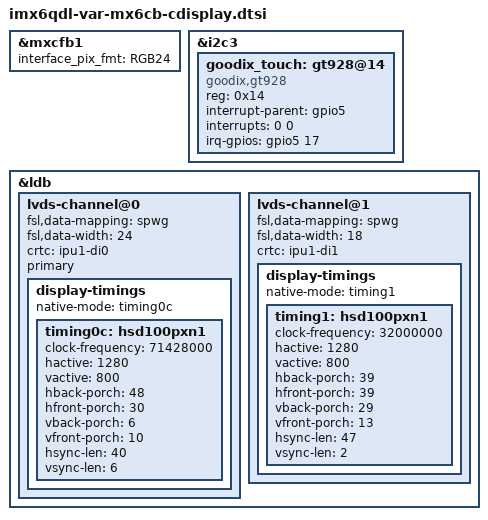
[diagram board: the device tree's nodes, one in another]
/*
 * Copyright (C) 2016 Variscite, Ltd. All Rights Reserved
 *
 * Copyright 2012 Freescale Semiconductor, Inc.
 * Copyright 2011 Linaro Ltd.
 *
 * The code contained herein is licensed under the GNU General Public
 * License. You may obtain a copy of the GNU General Public License
 * Version 2 or later at the following locations:
 *
 * http://www.opensource.org/licenses/gpl-license.html
 * http://www.gnu.org/copyleft/gpl.html
 *
 * Capacitive Display for VAR-MX6CustomBoard
 */

&mxcfb1 {
	interface_pix_fmt = "RGB24";
};

&i2c3 {
        goodix_touch: gt928@14 {
                compatible = "goodix,gt928";
                reg = <0x14>;
                interrupt-parent = <&gpio5>;
                interrupts = <0 0>;
                irq-gpios = <&gpio5 17>;
        };
};

&ldb {
	status = "okay";

	lvds-channel@0 {
		fsl,data-mapping = "spwg";
		fsl,data-width = <24>;
		status = "okay";
                crtc = "ipu1-di0";       /* ?? */
		primary;

		display-timings {
			native-mode = <&timing0c>;
			timing0c: hsd100pxn1 {
				clock-frequency = <71428000>;
				hactive = <1280>;
				vactive = <800>;
				hback-porch = <48>;
				hfront-porch = <30>;
				vback-porch = <6>;
				vfront-porch = <10>;
				hsync-len = <40>;
				vsync-len = <6>;
			};
		};
	};

	lvds-channel@1 {
		fsl,data-mapping = "spwg";
		fsl,data-width = <18>;
		status = "okay";
                crtc = "ipu1-di1";       /* ?? */

		display-timings {
			native-mode = <&timing1>;
			timing1: hsd100pxn1 {
				clock-frequency = <32000000>;
				hactive = <1280>;
				vactive = <800>;
				hback-porch = <39>;
				hfront-porch = <39>;
				vback-porch = <29>;
				vfront-porch = <13>;
				hsync-len = <47>;
				vsync-len = <2>;
			};
		};
	};
};
